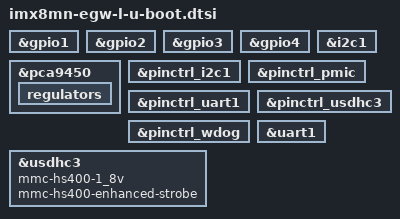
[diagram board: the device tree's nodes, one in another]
// SPDX-License-Identifier: GPL-2.0-or-later
/*
 * Copyright (c) 2023 - 2024 TQ-Systems GmbH <u-boot@ew.tq-group.com>,
 * D-82229 Seefeld, Germany.
 * Author: Michael Krummsdorf
 */

#include "imx8mn-u-boot.dtsi"

&gpio1 {
	bootph-pre-ram;
};

&gpio2 {
	bootph-pre-ram;
};

&gpio3 {
	bootph-pre-ram;
};

&gpio4 {
	bootph-pre-ram;
};

&i2c1 {
	bootph-pre-ram;
};

&pca9450 {
	bootph-pre-ram;

	regulators {
		bootph-pre-ram;
	};
};

&pinctrl_i2c1 {
	bootph-pre-ram;
};

&pinctrl_pmic {
	bootph-pre-ram;
};

&pinctrl_uart1 {
	bootph-pre-ram;
};

&pinctrl_usdhc3 {
	bootph-pre-ram;
};

&pinctrl_wdog {
	bootph-pre-ram;
};

&uart1 {
	bootph-pre-ram;
};

&usdhc3 {
	bootph-pre-ram;
	mmc-hs400-1_8v;
	mmc-hs400-enhanced-strobe;
};
